# CEC1702 register map
Vendor: Microchip
Registers are 32-bit, read-write, reset 0x0 unless marked. A register's access mark holds for its fields unless they carry their own. Addresses are absolute, and some are shared; only a register's first bit layout is shown; [hi:lo] are bit positions; {n}, {i} and the like mark numbered series; 'fields as' and 'values as' point back to an identical list.

## RTC
0x400F5000 SEC 8-bit
0x400F5001 SEC_ALARM 8-bit
0x400F5002 MIN 8-bit
0x400F5003 MIN_ALARM 8-bit
0x400F5004 HR 8-bit
0x400F5005 HR_ALARM 8-bit
0x400F5006 DAY_OF_WK 8-bit
0x400F5007 DAY_OF_MON 8-bit
0x400F5008 MONTH 8-bit
0x400F5009 YEAR 8-bit
0x400F500A REGA 8-bit
0x400F500B REGB 8-bit
0x400F500C REGC 8-bit
0x400F500D REGD 8-bit
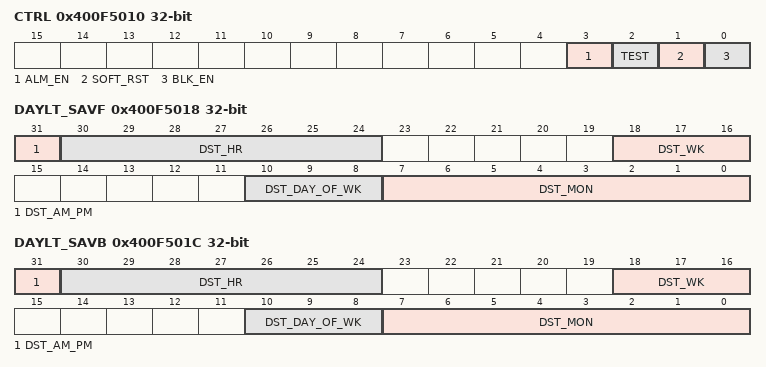
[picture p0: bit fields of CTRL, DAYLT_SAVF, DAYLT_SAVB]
0x400F5010 CTRL
  [3] ALM_EN — ALM_EN 1=Enables the Alarm features, 0=Disables the Alarm features
  [2] TEST
  [1] SOFT_RST — SOFT_RST A '1' written to this bit position will trigger the RTC_RST reset, resetting the block and all registers except this one and the Test Register. This bit is self-clearing at the end of the reset, one cycle of Host Bus Clock later, and so requires no waiting.
  [0] BLK_EN — BLK_EN This bit must be '1' in order for the block to function internally. Registers may be initialized first, before setting this bit to '1' to start operation.
0x400F5014 WK_ALARM
0x400F5018 DAYLT_SAVF
  [31] DST_AM_PM — This bit selects AM vs. PM, to match bit[7] of the Hours Register if 12-Hour mode is selected in Register B at the time of writing.
  [30:24] DST_HR — This field holds the matching value for bits[6:0] of the Hours register. The written value will be interpreted according to the 24/12 Hour mode and DM mode settings at the time of writing.
  [18:16] DST_WK — 5=Last week of month, 4 =Fourth week of month, 3=Third week of month, 2=Second week of month, 1=First week of month
  [10:8] DST_DAY_OF_WK — This field matches the Day of Week Register bits[2:0].
  [7:0] DST_MON — This field matches the Month Register.
0x400F501C DAYLT_SAVB
  fields as DAYLT_SAVF

## GCR
0x400FFF07 LDN 8-bit
0x400FFF20 DEV_ID 8-bit ro reset 0x31
0x400FFF21 DEV_REV 8-bit ro

## SFR
0xE000E004 ICTR ro reset not defined — Interrupt Controller Type Register (power-on value xxxxxxxxxxxxxxxxxxxxxxxxxxxxxxxx)
  [3:0] INTLINESNUM — Number of interrupt lines supported by NVIC in granularities of 32.

## SysTick
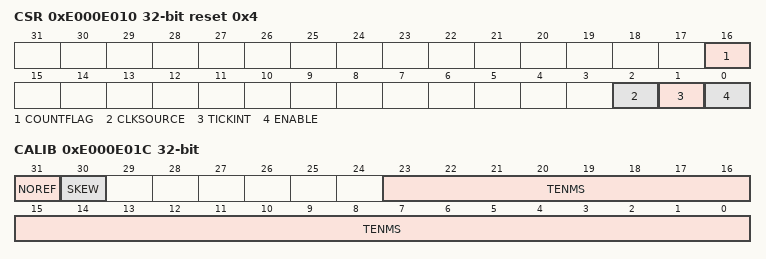
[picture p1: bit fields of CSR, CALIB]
0xE000E010 CSR reset 0x4
  [16] COUNTFLAG — Timer counted to 0 since last read of register
  [2] CLKSOURCE — Clock Source 0=external, 1=processor
    0=External clock; 1=Processor clock
  [1] TICKINT — SysTick Exception Request Enable
    0=Counting down to 0 does not assert the SysTick exception request; 1=Counting down to 0 asserts the SysTick exception request
  [0] ENABLE — SysTick Counter Enable
    0=Counter disabled; 1=Counter enabled
0xE000E014 RVR reset not defined
  [23:0] RELOAD — Value to load into the SysTick Current Value Register when the counter reaches 0
0xE000E018 CVR reset not defined
  [23:0] CURRENT — Current value at the time the register is accessed
0xE000E01C CALIB ro
  [31] NOREF — No Separate Reference Clock
    0=The reference clock is provided; 1=The reference clock is not provided
  [30] SKEW — TENMS is rounded from non-integer ratio
    0=10ms calibration value is exact; 1=10ms calibration value is inexact, because of the clock frequency
  [23:0] TENMS — Reload value to use for 10ms timing

## NVIC
0xE000E100 ISER0
  [31:0] SETENA — Interrupt set enable bits
0xE000E180 ICER0
  [31:0] CLRENA — Interrupt clear-enable bits
0xE000E200 ISPR0
  [31:0] SETPEND — Interrupt set-pending bits
0xE000E280 ICPR0
  [31:0] CLRPEND — Interrupt clear-pending bits
0xE000E300 IABR0
  [31:0] ACTIVE — Interrupt active bits
{0xE000E400+i} IP{i} 8-bit (i=0..7)
  [2:0] PRI0 — Priority of interrupt n
0xE000EF00 STIR wo reset not defined
  [8:0] INTID — Interrupt ID to trigger

## MPU
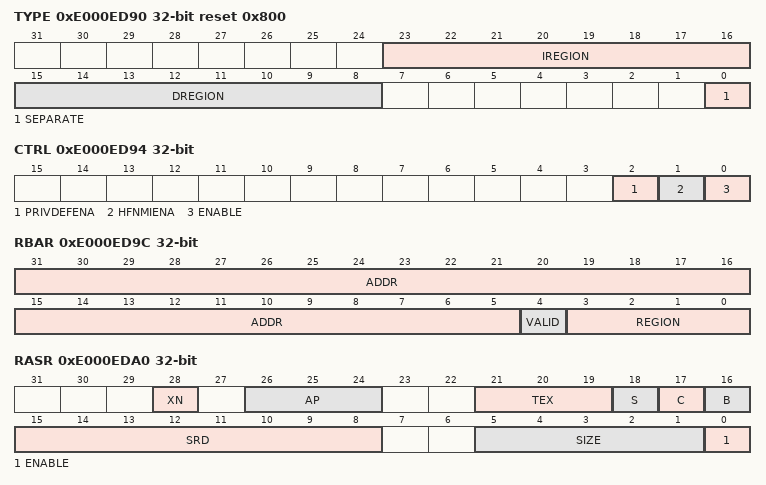
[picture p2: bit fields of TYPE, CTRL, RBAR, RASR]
0xE000ED90 TYPE ro reset 0x800
  [23:16] IREGION — Indicates the number of supported MPU data regions.
  [15:8] DREGION — Indicates the number of supported MPU instruction regions.
  [0] SEPARATE — Indicates support for unified or separate instruction and date memory maps.
0xE000ED94 CTRL
  [2] PRIVDEFENA — Enables privileged software access to the default memory map.
  [1] HFNMIENA — Enables the operation of MPU during hard fault, NMI, and FAULTMASK handlers.
  [0] ENABLE — Enables the MPU
0xE000ED98 RNR
  [7:0] REGION — Indicates the MPU region referenced by the MPU_RBAR and MPU_RASR registers.
0xE000ED9C RBAR
  [31:5] ADDR — Region base address field.
  [4] VALID — MPU Region Number valid bit.
  [3:0] REGION — MPU region field.
0xE000EDA0 RASR
  [28] XN — Instruction access disable bit.
  [26:24] AP — Access permission field.
  [21:19] TEX — MPU access permission attributes.
  [18] S — Shareable bit.
  [17] C — MPU access permission attributes.
  [16] B — MPU access permission attributes.
  [15:8] SRD — Subregion disable bits.
  [5:1] SIZE — Specifies the size of the MPU protection region.
  [0] ENABLE — Region enable bit.
